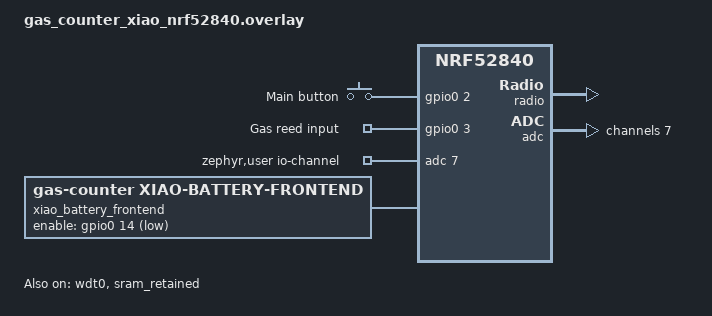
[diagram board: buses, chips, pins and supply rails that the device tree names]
/*
 * Copyright (c) 2025 Nordic Semiconductor ASA
 *
 * SPDX-License-Identifier: LicenseRef-Nordic-5-Clause
 */
/ {

    aliases {
        main-button = &main_button;
        reed-input = &reed_input;
        watchdog0 = &wdt0;
        xiao-read-bat-enable = &xiao_battery_frontend;
        xiao-led-red = &led0;
        xiao-led-green = &led1;
        xiao-led-blue = &led2;
    };

    app_gpios {
        compatible = "gpio-keys";

        main_button: main_button {
            gpios = <&gpio0 2 (GPIO_PULL_DOWN | GPIO_ACTIVE_HIGH)>;
            label = "Main button";
        };

        reed_input: reed_input {
            gpios = <&gpio0 3 (GPIO_PULL_DOWN | GPIO_ACTIVE_HIGH)>;
            label = "Gas reed input";
        };
    };

    zephyr,user {
        io-channels = <&adc 7>; /* P0.31 = AIN7_BAT */
    };

    sram_retained: sram@2003ff00 {
        compatible = "zephyr,memory-region", "mmio-sram";
        reg = <0x2003ff00 0x100>;
        zephyr,memory-region = "RetainedMem";
        status = "okay";

        retainedmem {
            compatible = "zephyr,retained-ram";
            status = "okay";
            #address-cells = <1>;
            #size-cells = <1>;

            gm_retention: retention@0 {
                compatible = "zephyr,retention";
                reg = <0x0 0x100>;
                status = "okay";
                prefix = [47 4d]; /* "GM" */
                checksum = <4>;
            };
        };
    };

    xiao_battery_frontend: xiao_battery_frontend {
        compatible = "gas-counter,xiao-battery-frontend";
        enable-gpios = <&gpio0 14 GPIO_ACTIVE_LOW>;
        status = "okay";
    };
};

&sram0 {
    reg = <0x20000000 0x3ff00>;
};

&radio {
    status = "okay";
    zephyr,deferred-init;
};

&wdt0 {
    status = "okay";
};

&adc {
    status = "okay";

    #address-cells = <1>;
    #size-cells = <0>;

    channel@7 {
        reg = <7>;
        zephyr,gain = "ADC_GAIN_1_6";
        zephyr,reference = "ADC_REF_INTERNAL";
        zephyr,acquisition-time = <ADC_ACQ_TIME(ADC_ACQ_TIME_MICROSECONDS, 40)>;
        zephyr,input-positive = <NRF_SAADC_AIN7>;
        zephyr,resolution = <12>;
        zephyr,oversampling = <4>;
    };
};

&gpio0 {
	latch-detect;
	sense-edge-mask = <0x0000000c>; /* BIT(2) | BIT(3) */
};

/delete-node/ &i2c1;
/delete-node/ &qspi;
/delete-node/ &spi2;

/delete-node/ &slot0_partition;
/delete-node/ &slot1_partition;
/delete-node/ &storage_partition;

&flash0 {
    partitions {
        boot_partition: partition@0 {
            compatible = "zephyr,mapped-partition";
            label = "mcuboot";
            reg = <0x00000 DT_SIZE_K(48)>;
        };

        slot0_partition: partition@0C000 {
            compatible = "zephyr,mapped-partition";
            label = "image-0";
            reg = <0x0C000 DT_SIZE_K(464)>;
        };

        slot1_partition: partition@80000 {
            compatible = "zephyr,mapped-partition";
            label = "image-1";
            reg = <0x80000 DT_SIZE_K(464)>;
        };

        storage_partition: partition@f8000 {
            compatible = "zephyr,mapped-partition";
            label = "storage";
            reg = <0xf8000 DT_SIZE_K(20)>;
        };

        zboss_nvram: partition@fd000 {
            compatible = "zephyr,mapped-partition";
            label = "zboss-nvram";
            reg = <0xfd000 DT_SIZE_K(8)>;
        };

        zboss_product_config: partition@ff000 {
            compatible = "zephyr,mapped-partition";
            label = "zboss-product-config";
            reg = <0xff000 DT_SIZE_K(4)>;
        };
    };
};
